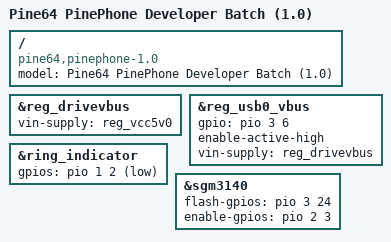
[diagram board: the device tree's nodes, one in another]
// SPDX-License-Identifier: (GPL-2.0+ OR MIT)
// Copyright (C) 2020 Ondrej Jirman <megous@megous.com>

/dts-v1/;

#include "sun50i-a64-pinephone.dtsi"

/ {
	model = "Pine64 PinePhone Developer Batch (1.0)";
	compatible = "pine64,pinephone-1.0", "allwinner,sun50i-a64";
};

/*
 * The N_VBUSEN pin is disconnected, but we need to inform the PMIC about
 * the VBUS status anyway. To avoid the pin from floating and to inform
 * the PMIC, about VBUS status, we couple reg_drivevbus with reg_vbus.
 */
&reg_drivevbus {
	vin-supply = <&reg_vcc5v0>;
	status = "okay";
};

&reg_usb0_vbus {
	gpio = <&pio 3 6 GPIO_ACTIVE_HIGH>; /* PD6 */
	enable-active-high;
	vin-supply = <&reg_drivevbus>;
};

&ring_indicator {
	gpios = <&pio 1 2 GPIO_ACTIVE_LOW>; /* PB2 */
};

&sgm3140 {
	flash-gpios = <&pio 3 24 GPIO_ACTIVE_HIGH>; /* PD24 */
	enable-gpios = <&pio 2 3 GPIO_ACTIVE_HIGH>; /* PC3 */
};
